# HR_C7000_DM32 register map
Vendor: Dahua Technology (chip); Baofeng (radio product); Series: HR_C7000; File version: 0.1-dm32re-draft
CPU: other r0p0, little endian, no MPU, no FPU, 0 interrupt priority bits
Registers are 32-bit, read-write, reset 0x0 unless marked. A register's access mark holds for its fields unless they carry their own. Offsets are from the block's base; [hi:lo] are bit positions; {n}, {i} and the like mark numbered series; <NAME> marks a mode.

## PIC (part 2 of 2) — Programmable interrupt controller, 64 sources of which Table 30 assigns 38 (DS §4.7, p.166-187; Register Table 5 p.170-172). This is the chip's real interrupt controller, not the CK803S built-in VIC at 0xE000E100: the stock firmware makes no 0xE000xxxx accesses (program-flash sweep and live register reads). SOURCE vs VECTOR: source n is bit n of PIC_MODE/PO/MASK/INT_ST/FFLAG_L (n < 32) or bit n-32 of PIC_MODE_1/PO_1/MASK_1/INT_ST_1/FFLAG_H, and byte n%4 of PIC_PRIOR<4*(n/4)>; the CPU sees it as vector n + PIC_VECTOR.vector0 = n + 32 at reset. Table 30 (p.168-169), source/vector: 0 reserved/32, 1 TIMER_1/33, 2 TIMER_2/34, 3 TIMER_3/35, 4 TIMER_4/36, 5 TIMER_5/37, 6 TIMER_6/38, 7 I2C1/39, 8 I2C0/40, 9 I2C2/41, 10 UART1/42, 11 UART2/43, 12 UART0/44, 13 UART3/45, 14 GPIOB/46, 15 GPIOA/47, 16 SPI0/48, 17 GPIOC/49, 18 PWM/50, 19 RTC/51, 20 SDIO/52, 21 USB/53, 22 SPI1/54, 23 SPI2/55, 24 LCSFC/56, 25 DAC/57, 26 ADC/58, 27 PCM_rd_data_interp/59, 28 PCM_wr_data_interp/60, 29 System_inter/61, 30 Time_slot_inter_tx/62, 31 Time_slot_inter_rx/63, 32 Rf_tx_inter/64, 33 Rf_rx_inter/65, 34 SlaveSPI0/66, 35 SlaveSPI1/67, 36 SlaveSPI2/68, 37 Codec_interp/69; all level-triggered, active high. CORRECTED 2026-10-10: the hand-maintained description this replaced listed CPU vectors as 'source assignments' (TIMER_1=33, TIMER_2-4=34-36, UART3=45, GPIOC=49, PCM_rd/wr_data_interp=59/60, System_inter=61, Time_slot_inter_rx=63, Rf_rx_inter=65, Codec_interp=69, and UART1/2/0=42/43/44, ADC=58, Rf_tx=64). Those are vectors; the sources are 1, 2-4, 13, 17, 27/28, 29, 31, 33, 37, 10/11/12, 26, 32. DRV's VECTOR_* defines (C7000_DRV.h: VECTOR_TIMER1-4=33-36, UART3=45, GPIOC=49, PCM_rd/wr_data_interp=59/60, System_inter=61, Time_slot_inter_rx=63, Rf_rx_inter=65, Codec_interp=69; bsp_vic.h: VECTOR_TIMER0=33, VECTOR_USB=53) are vectors too, passed to CKSetIsrVector, which unmasks bit (vector - 32); they agree with Table 30's vector column at every entry. The earlier note that a live trace's 'Time_slot_inter_tx = source 30' and DRV's 'Time_slot_inter_rx = 63' were an unverified TX/RX pair is resolved: Table 30 has tx at source 30/vector 62 and rx at source 31/vector 63. RTOS TICK: TIMER_1 (timer channel 0) is PIC source 1, CPU vector 33. Confirmed on hardware 2026-10-01 (OpenRTX bring-up on a DM-32UV, boot console log): with source 33 unmasked instead, the timer expired and held its line but nothing was delivered; with source 1 unmasked the ISR fired. The stock firmware registers its tick ISR with vector 33, stored at ISR-table index 33 - 32 = 1 (flash 0x0306cf70/0x0306cf38; dm32uv-qemu board-model notes (DM32-BOARD-MODEL.md), session 7). Register names and offsets also come from DRV bsp_vic.h ('Interrupt Controller definitions', Wang Huibin, 2013-05-13; in the DemoUV008 source tree at ucos3/include/bsp/bsp_vic.h), which agrees with Register Table 5 at every offset. Its CKIntcInit (bsp_vic.c) writes MODE = 0, PO = 0xffffffff, MASK = 0xffffffff, MODE_1 = 0, PO_1 = 0xffffffff, then MASK a second time where MASK_1 was probably meant, then INT_ST/INT_ST_1 = 0xffffffff. FW: 24 access sites in 2 code regions, all to MODE/PO/MASK/INT_ST and their upper-bank siblings; no access to PIC_VECTOR, PIC_COW1/2, PIC_PRIOR*, PIC_SYNC or PIC_FFLAG_* was found by the program-flash sweep, which does not cover IRAM (where the interrupt entry path runs).
Base 0x17000000
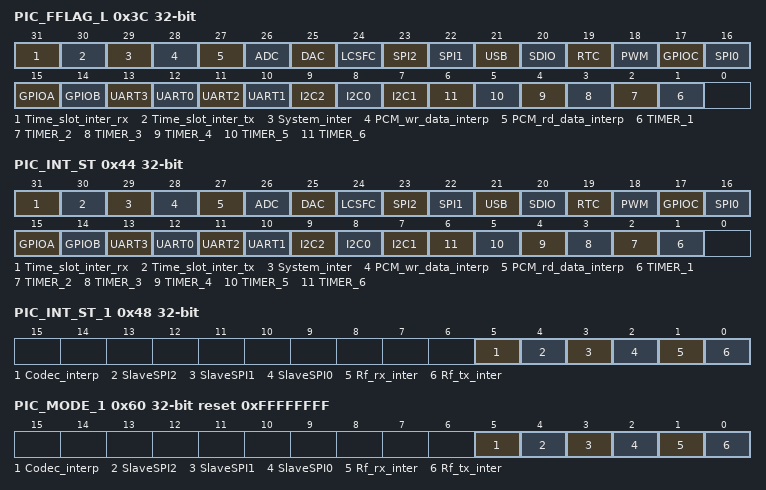
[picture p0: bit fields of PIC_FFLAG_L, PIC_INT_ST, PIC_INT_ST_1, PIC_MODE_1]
0x3C PIC_FFLAG_L — Fast-interrupt select, sources 0-31. DS §4.7.6.16 p.180. Bit n is source 0+n (sources 0-31). The datasheet prints one [31:0] field; it is split here into one bit per source named in Table 30 (p.168-169); bits with no assigned source have no field. The hand-maintained entry this replaced guessed a pending-interrupt flag word; it is the fast-interrupt select. Offset also in DRV bsp_vic.h. Reset 0x0 (DS).
  [31] Time_slot_inter_rx — source 31 (Time_slot_inter_rx, vector 63). 1: fast interrupt; 0: normal interrupt. The C7000 supports only normal interrupts (DS §4.7.4.1 p.170) [reset 0x0] [access RW]
  [30] Time_slot_inter_tx — source 30 (Time_slot_inter_tx, vector 62). 1: fast interrupt; 0: normal interrupt. The C7000 supports only normal interrupts (DS §4.7.4.1 p.170) [reset 0x0] [access RW]
  [29] System_inter — source 29 (System_inter, vector 61). 1: fast interrupt; 0: normal interrupt. The C7000 supports only normal interrupts (DS §4.7.4.1 p.170) [reset 0x0] [access RW]
  [28] PCM_wr_data_interp — source 28 (PCM_wr_data_interp, vector 60). 1: fast interrupt; 0: normal interrupt. The C7000 supports only normal interrupts (DS §4.7.4.1 p.170) [reset 0x0] [access RW]
  [27] PCM_rd_data_interp — source 27 (PCM_rd_data_interp, vector 59). 1: fast interrupt; 0: normal interrupt. The C7000 supports only normal interrupts (DS §4.7.4.1 p.170) [reset 0x0] [access RW]
  [26] ADC — source 26 (ADC, vector 58). 1: fast interrupt; 0: normal interrupt. The C7000 supports only normal interrupts (DS §4.7.4.1 p.170) [reset 0x0] [access RW]
  [25] DAC — source 25 (DAC, vector 57). 1: fast interrupt; 0: normal interrupt. The C7000 supports only normal interrupts (DS §4.7.4.1 p.170) [reset 0x0] [access RW]
  [24] LCSFC — source 24 (LCSFC, vector 56). 1: fast interrupt; 0: normal interrupt. The C7000 supports only normal interrupts (DS §4.7.4.1 p.170) [reset 0x0] [access RW]
  [23] SPI2 — source 23 (SPI2, vector 55). 1: fast interrupt; 0: normal interrupt. The C7000 supports only normal interrupts (DS §4.7.4.1 p.170) [reset 0x0] [access RW]
  [22] SPI1 — source 22 (SPI1, vector 54). 1: fast interrupt; 0: normal interrupt. The C7000 supports only normal interrupts (DS §4.7.4.1 p.170) [reset 0x0] [access RW]
  [21] USB — source 21 (USB, vector 53). 1: fast interrupt; 0: normal interrupt. The C7000 supports only normal interrupts (DS §4.7.4.1 p.170) [reset 0x0] [access RW]
  [20] SDIO — source 20 (SDIO, vector 52). 1: fast interrupt; 0: normal interrupt. The C7000 supports only normal interrupts (DS §4.7.4.1 p.170) [reset 0x0] [access RW]
  [19] RTC — source 19 (RTC, vector 51). 1: fast interrupt; 0: normal interrupt. The C7000 supports only normal interrupts (DS §4.7.4.1 p.170) [reset 0x0] [access RW]
  [18] PWM — source 18 (PWM, vector 50). 1: fast interrupt; 0: normal interrupt. The C7000 supports only normal interrupts (DS §4.7.4.1 p.170) [reset 0x0] [access RW]
  [17] GPIOC — source 17 (GPIOC, vector 49). 1: fast interrupt; 0: normal interrupt. The C7000 supports only normal interrupts (DS §4.7.4.1 p.170) [reset 0x0] [access RW]
  [16] SPI0 — source 16 (SPI0, vector 48). 1: fast interrupt; 0: normal interrupt. The C7000 supports only normal interrupts (DS §4.7.4.1 p.170) [reset 0x0] [access RW]
  [15] GPIOA — source 15 (GPIOA, vector 47). 1: fast interrupt; 0: normal interrupt. The C7000 supports only normal interrupts (DS §4.7.4.1 p.170) [reset 0x0] [access RW]
  [14] GPIOB — source 14 (GPIOB, vector 46). 1: fast interrupt; 0: normal interrupt. The C7000 supports only normal interrupts (DS §4.7.4.1 p.170) [reset 0x0] [access RW]
  [13] UART3 — source 13 (UART3, vector 45). 1: fast interrupt; 0: normal interrupt. The C7000 supports only normal interrupts (DS §4.7.4.1 p.170) [reset 0x0] [access RW]
  [12] UART0 — source 12 (UART0, vector 44). 1: fast interrupt; 0: normal interrupt. The C7000 supports only normal interrupts (DS §4.7.4.1 p.170) [reset 0x0] [access RW]
  [11] UART2 — source 11 (UART2, vector 43). 1: fast interrupt; 0: normal interrupt. The C7000 supports only normal interrupts (DS §4.7.4.1 p.170) [reset 0x0] [access RW]
  [10] UART1 — source 10 (UART1, vector 42). 1: fast interrupt; 0: normal interrupt. The C7000 supports only normal interrupts (DS §4.7.4.1 p.170) [reset 0x0] [access RW]
  [9] I2C2 — source 9 (I2C2, vector 41). 1: fast interrupt; 0: normal interrupt. The C7000 supports only normal interrupts (DS §4.7.4.1 p.170) [reset 0x0] [access RW]
  [8] I2C0 — source 8 (I2C0, vector 40). 1: fast interrupt; 0: normal interrupt. The C7000 supports only normal interrupts (DS §4.7.4.1 p.170) [reset 0x0] [access RW]
  [7] I2C1 — source 7 (I2C1, vector 39). 1: fast interrupt; 0: normal interrupt. The C7000 supports only normal interrupts (DS §4.7.4.1 p.170) [reset 0x0] [access RW]
  [n] TIMER_{n} (n=1..6) — source {n} (TIMER_{n}, vector {n+32}). 1: fast interrupt; 0: normal interrupt. The C7000 supports only normal interrupts (DS §4.7.4.1 p.170) [reset 0x0] [access RW]
0x40 PIC_RECORD_SEL — Selects the source whose requests PIC_INT_CNT counts. DS §4.7.6.17 p.180. Section heading prints PIC_INT_RECORD_SEL; Register Table 5 (p.172) and DRV bsp_vic.h call it PIC_RECORD_SEL, which is kept. Reset 0x0 (DS).
  [6:0] irq_record_sel — Source number whose requests (after synchronisation and masking) are counted in PIC_INT_CNT [reset 0x0] [access RW]
0x44 PIC_INT_ST — Interrupt request record, sources 0-31. DS §4.7.6.18 p.180. FW: 0 reads, 2 writes. Bit n is source 0+n (sources 0-31). The datasheet prints one [31:0] field; it is split here into one bit per source named in Table 30 (p.168-169); bits with no assigned source have no field. Write 0xffffffff to clear all records (DS §4.7.4.1 step 4). A 2026-10-09 firmware cross-reference found this word written all-ones at startup before the name was known, and DRV bsp_vic.h names it. Reset 0x0 (DS).
  [31] Time_slot_inter_rx write-1-clears — Request record for source 31 (Time_slot_inter_rx, vector 63): 1 = a request was seen (recorded once). Write 1 to clear the record and PIC_INT_CNT. Printed access RWC [reset 0x0] [access RWC]
  [30] Time_slot_inter_tx write-1-clears — Request record for source 30 (Time_slot_inter_tx, vector 62): 1 = a request was seen (recorded once). Write 1 to clear the record and PIC_INT_CNT. Printed access RWC [reset 0x0] [access RWC]
  [29] System_inter write-1-clears — Request record for source 29 (System_inter, vector 61): 1 = a request was seen (recorded once). Write 1 to clear the record and PIC_INT_CNT. Printed access RWC [reset 0x0] [access RWC]
  [28] PCM_wr_data_interp write-1-clears — Request record for source 28 (PCM_wr_data_interp, vector 60): 1 = a request was seen (recorded once). Write 1 to clear the record and PIC_INT_CNT. Printed access RWC [reset 0x0] [access RWC]
  [27] PCM_rd_data_interp write-1-clears — Request record for source 27 (PCM_rd_data_interp, vector 59): 1 = a request was seen (recorded once). Write 1 to clear the record and PIC_INT_CNT. Printed access RWC [reset 0x0] [access RWC]
  [26] ADC write-1-clears — Request record for source 26 (ADC, vector 58): 1 = a request was seen (recorded once). Write 1 to clear the record and PIC_INT_CNT. Printed access RWC [reset 0x0] [access RWC]
  [25] DAC write-1-clears — Request record for source 25 (DAC, vector 57): 1 = a request was seen (recorded once). Write 1 to clear the record and PIC_INT_CNT. Printed access RWC [reset 0x0] [access RWC]
  [24] LCSFC write-1-clears — Request record for source 24 (LCSFC, vector 56): 1 = a request was seen (recorded once). Write 1 to clear the record and PIC_INT_CNT. Printed access RWC [reset 0x0] [access RWC]
  [23] SPI2 write-1-clears — Request record for source 23 (SPI2, vector 55): 1 = a request was seen (recorded once). Write 1 to clear the record and PIC_INT_CNT. Printed access RWC [reset 0x0] [access RWC]
  [22] SPI1 write-1-clears — Request record for source 22 (SPI1, vector 54): 1 = a request was seen (recorded once). Write 1 to clear the record and PIC_INT_CNT. Printed access RWC [reset 0x0] [access RWC]
  [21] USB write-1-clears — Request record for source 21 (USB, vector 53): 1 = a request was seen (recorded once). Write 1 to clear the record and PIC_INT_CNT. Printed access RWC [reset 0x0] [access RWC]
  [20] SDIO write-1-clears — Request record for source 20 (SDIO, vector 52): 1 = a request was seen (recorded once). Write 1 to clear the record and PIC_INT_CNT. Printed access RWC [reset 0x0] [access RWC]
  [19] RTC write-1-clears — Request record for source 19 (RTC, vector 51): 1 = a request was seen (recorded once). Write 1 to clear the record and PIC_INT_CNT. Printed access RWC [reset 0x0] [access RWC]
  [18] PWM write-1-clears — Request record for source 18 (PWM, vector 50): 1 = a request was seen (recorded once). Write 1 to clear the record and PIC_INT_CNT. Printed access RWC [reset 0x0] [access RWC]
  [17] GPIOC write-1-clears — Request record for source 17 (GPIOC, vector 49): 1 = a request was seen (recorded once). Write 1 to clear the record and PIC_INT_CNT. Printed access RWC [reset 0x0] [access RWC]
  [16] SPI0 write-1-clears — Request record for source 16 (SPI0, vector 48): 1 = a request was seen (recorded once). Write 1 to clear the record and PIC_INT_CNT. Printed access RWC [reset 0x0] [access RWC]
  [15] GPIOA write-1-clears — Request record for source 15 (GPIOA, vector 47): 1 = a request was seen (recorded once). Write 1 to clear the record and PIC_INT_CNT. Printed access RWC [reset 0x0] [access RWC]
  [14] GPIOB write-1-clears — Request record for source 14 (GPIOB, vector 46): 1 = a request was seen (recorded once). Write 1 to clear the record and PIC_INT_CNT. Printed access RWC [reset 0x0] [access RWC]
  [13] UART3 write-1-clears — Request record for source 13 (UART3, vector 45): 1 = a request was seen (recorded once). Write 1 to clear the record and PIC_INT_CNT. Printed access RWC [reset 0x0] [access RWC]
  [12] UART0 write-1-clears — Request record for source 12 (UART0, vector 44): 1 = a request was seen (recorded once). Write 1 to clear the record and PIC_INT_CNT. Printed access RWC [reset 0x0] [access RWC]
  [11] UART2 write-1-clears — Request record for source 11 (UART2, vector 43): 1 = a request was seen (recorded once). Write 1 to clear the record and PIC_INT_CNT. Printed access RWC [reset 0x0] [access RWC]
  [10] UART1 write-1-clears — Request record for source 10 (UART1, vector 42): 1 = a request was seen (recorded once). Write 1 to clear the record and PIC_INT_CNT. Printed access RWC [reset 0x0] [access RWC]
  [9] I2C2 write-1-clears — Request record for source 9 (I2C2, vector 41): 1 = a request was seen (recorded once). Write 1 to clear the record and PIC_INT_CNT. Printed access RWC [reset 0x0] [access RWC]
  [8] I2C0 write-1-clears — Request record for source 8 (I2C0, vector 40): 1 = a request was seen (recorded once). Write 1 to clear the record and PIC_INT_CNT. Printed access RWC [reset 0x0] [access RWC]
  [7] I2C1 write-1-clears — Request record for source 7 (I2C1, vector 39): 1 = a request was seen (recorded once). Write 1 to clear the record and PIC_INT_CNT. Printed access RWC [reset 0x0] [access RWC]
  [n] TIMER_{n} write-1-clears (n=1..6) — Request record for source {n} (TIMER_{n}, vector {n+32}): 1 = a request was seen (recorded once). Write 1 to clear the record and PIC_INT_CNT. Printed access RWC [reset 0x0] [access RWC]
0x48 PIC_INT_ST_1 — Interrupt request record, sources 32-63. DS §4.7.6.19 p.181. FW: 0 reads, 2 writes. Bit n is source 32+n (sources 32-63). The datasheet prints one [31:0] field; it is split here into one bit per source named in Table 30 (p.168-169); bits with no assigned source have no field. Same history as PIC_INT_ST. Reset 0x0 (DS).
  [5] Codec_interp write-1-clears — Request record for source 37 (Codec_interp, vector 69): 1 = a request was seen (recorded once). Write 1 to clear the record and PIC_INT_CNT. Printed access RWC [reset 0x0] [access RWC]
  [4] SlaveSPI2 write-1-clears — Request record for source 36 (SlaveSPI2, vector 68): 1 = a request was seen (recorded once). Write 1 to clear the record and PIC_INT_CNT. Printed access RWC [reset 0x0] [access RWC]
  [3] SlaveSPI1 write-1-clears — Request record for source 35 (SlaveSPI1, vector 67): 1 = a request was seen (recorded once). Write 1 to clear the record and PIC_INT_CNT. Printed access RWC [reset 0x0] [access RWC]
  [2] SlaveSPI0 write-1-clears — Request record for source 34 (SlaveSPI0, vector 66): 1 = a request was seen (recorded once). Write 1 to clear the record and PIC_INT_CNT. Printed access RWC [reset 0x0] [access RWC]
  [1] Rf_rx_inter write-1-clears — Request record for source 33 (Rf_rx_inter, vector 65): 1 = a request was seen (recorded once). Write 1 to clear the record and PIC_INT_CNT. Printed access RWC [reset 0x0] [access RWC]
  [0] Rf_tx_inter write-1-clears — Request record for source 32 (Rf_tx_inter, vector 64): 1 = a request was seen (recorded once). Write 1 to clear the record and PIC_INT_CNT. Printed access RWC [reset 0x0] [access RWC]
0x4C PIC_INT_CNT ro — Interrupt source interrupt count. DS §4.7.6.20 p.181. Section heading prints PIC_INT_ST_CNT at offset 0x48, which collides with PIC_INT_ST_1 (both editions); Register Table 5 (p.172) and DRV bsp_vic.h give PIC_INT_CNT at 0x4c, which is used. The hand-maintained entry this replaced guessed a spurious/total counter; it counts only the source selected by PIC_RECORD_SEL. Reset 0x0 (DS).
  [31:0] int_cnt — Number of interrupt requests from the source selected by PIC_RECORD_SEL (printed PIC_INT_RECORD_SEL) [reset 0x0] [access RO]
0x60 PIC_MODE_1 reset 0xFFFFFFFF — Trigger mode select, sources 32-63 (Register Table 5 prints 'Height 32', i.e. the high 32). DS §4.7.6.21 p.182. FW: 0 reads, 2 writes. Bit n is source 32+n (sources 32-63). The datasheet prints one [31:0] field; it is split here into one bit per source named in Table 30 (p.168-169); bits with no assigned source have no field. A 2026-10-09 firmware cross-reference found this offset written all-ones at startup and labelled it RESERVED_0x60 before DRV bsp_vic.h gave the name. Reset 0xffffffff (DS).
  [5] Codec_interp — Trigger mode of source 37 (Codec_interp, vector 69). 1: edge; 0: level. Table 30 specifies level-triggered, active high [reset 0x1] [access RW]
  [4] SlaveSPI2 — Trigger mode of source 36 (SlaveSPI2, vector 68). 1: edge; 0: level. Table 30 specifies level-triggered, active high [reset 0x1] [access RW]
  [3] SlaveSPI1 — Trigger mode of source 35 (SlaveSPI1, vector 67). 1: edge; 0: level. Table 30 specifies level-triggered, active high [reset 0x1] [access RW]
  [2] SlaveSPI0 — Trigger mode of source 34 (SlaveSPI0, vector 66). 1: edge; 0: level. Table 30 specifies level-triggered, active high [reset 0x1] [access RW]
  [1] Rf_rx_inter — Trigger mode of source 33 (Rf_rx_inter, vector 65). 1: edge; 0: level. Table 30 specifies level-triggered, active high [reset 0x1] [access RW]
  [0] Rf_tx_inter — Trigger mode of source 32 (Rf_tx_inter, vector 64). 1: edge; 0: level. Table 30 specifies level-triggered, active high [reset 0x1] [access RW]
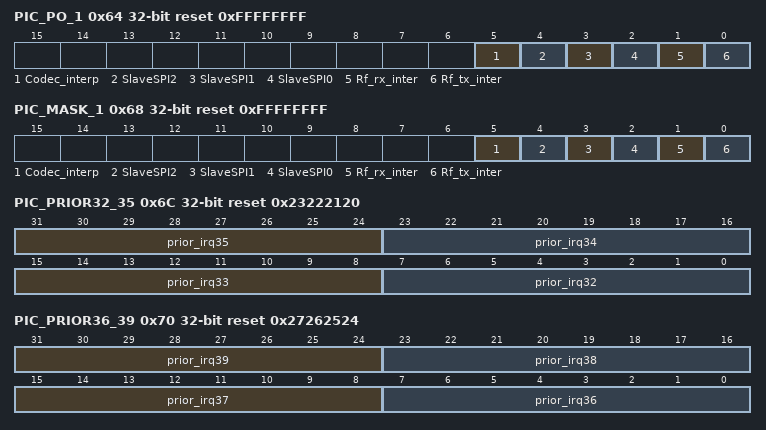
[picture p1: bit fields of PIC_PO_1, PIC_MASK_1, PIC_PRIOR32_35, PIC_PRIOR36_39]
0x64 PIC_PO_1 reset 0xFFFFFFFF — Trigger polarity select, sources 32-63 (Register Table 5 prints 'Height 32', i.e. the high 32). DS §4.7.6.22 p.182. FW: 0 reads, 2 writes. Bit n is source 32+n (sources 32-63). The datasheet prints one [31:0] field; it is split here into one bit per source named in Table 30 (p.168-169); bits with no assigned source have no field. Offset also in DRV bsp_vic.h. Reset 0xffffffff (DS).
  [5] Codec_interp — Trigger polarity of source 37 (Codec_interp, vector 69). 1: rising edge / high level; 0: falling edge / low level [reset 0x1] [access RW]
  [4] SlaveSPI2 — Trigger polarity of source 36 (SlaveSPI2, vector 68). 1: rising edge / high level; 0: falling edge / low level [reset 0x1] [access RW]
  [3] SlaveSPI1 — Trigger polarity of source 35 (SlaveSPI1, vector 67). 1: rising edge / high level; 0: falling edge / low level [reset 0x1] [access RW]
  [2] SlaveSPI0 — Trigger polarity of source 34 (SlaveSPI0, vector 66). 1: rising edge / high level; 0: falling edge / low level [reset 0x1] [access RW]
  [1] Rf_rx_inter — Trigger polarity of source 33 (Rf_rx_inter, vector 65). 1: rising edge / high level; 0: falling edge / low level [reset 0x1] [access RW]
  [0] Rf_tx_inter — Trigger polarity of source 32 (Rf_tx_inter, vector 64). 1: rising edge / high level; 0: falling edge / low level [reset 0x1] [access RW]
0x68 PIC_MASK_1 reset 0xFFFFFFFF — Interrupt mask, sources 32-63 (Register Table 5 prints 'Height 32', i.e. the high 32). DS §4.7.6.23 p.182. FW: 2 reads, 4 writes. Bit n is source 32+n (sources 32-63). The datasheet prints one [31:0] field; it is split here into one bit per source named in Table 30 (p.168-169); bits with no assigned source have no field. FW clears bit (v - 0x40) here for CPU vector v >= 0x40 (same two functions as PIC_MASK). Hardware, 2026-10-01 (OpenRTX bring-up on a DM-32UV, boot console log): an OpenRTX build that cleared bit 1 here (source 33) read PIC_MASK/PIC_MASK_1 = ffffffff/fffffffd, the timer counted and held its line, and no interrupt was delivered; clearing bit 1 of PIC_MASK (source 1, TIMER_1) made the tick ISR fire. Named PIC_MASK_HI in earlier drafts until DRV bsp_vic.h gave PIC_MASK_1 (2026-10-09). CORRECTED 2026-10-10: the entry this replaced said this word covers sources 64+; it covers 32-63. Reset 0xffffffff (DS).
  [5] Codec_interp — Mask for source 37 (Codec_interp, vector 69). 1: masked; 0: request detection enabled [reset 0x1] [access RW]
  [4] SlaveSPI2 — Mask for source 36 (SlaveSPI2, vector 68). 1: masked; 0: request detection enabled [reset 0x1] [access RW]
  [3] SlaveSPI1 — Mask for source 35 (SlaveSPI1, vector 67). 1: masked; 0: request detection enabled [reset 0x1] [access RW]
  [2] SlaveSPI0 — Mask for source 34 (SlaveSPI0, vector 66). 1: masked; 0: request detection enabled [reset 0x1] [access RW]
  [1] Rf_rx_inter — Mask for source 33 (Rf_rx_inter, vector 65). 1: masked; 0: request detection enabled [reset 0x1] [access RW]
  [0] Rf_tx_inter — Mask for source 32 (Rf_tx_inter, vector 64). 1: masked; 0: request detection enabled [reset 0x1] [access RW]
0x6C PIC_PRIOR32_35 reset 0x23222120 — Priority counter initial values, sources 32-35. DS §4.7.6.24 p.182. Sources 32-35 are Rf_tx_inter, Rf_rx_inter, SlaveSPI0, SlaveSPI1; one byte each, source 32 in [7:0]. Offset also in DRV bsp_vic.h as PIC_PRIOR32_35. FW: no access found by the program-flash sweep (which does not cover IRAM code). Both v2.7 editions print the defaults as 0x27/0x26/0x25/0x24 (for sources 35..32), the same values as PIC_PRIOR36-39, and print the rows in Chinese. Every other PRIOR register's default equals its source number, so 0x23/0x22/0x21/0x20 are used (INFERRED; reset 0x23222120 here, printed values would give 0x27262524). Reset 0x23222120 (DS).
  [31:24] prior_irq35 — Priority counter initial value for source 35 (SlaveSPI1, vector 67); smaller is higher priority. Used only when PIC_COW2.priority = 1. Reset value n gives the same order as the fixed default IRQ0 > IRQ1 > ... > IRQ63 [reset 0x23] [access RW]
  [23:16] prior_irq34 — Priority counter initial value for source 34 (SlaveSPI0, vector 66); smaller is higher priority. Used only when PIC_COW2.priority = 1. Reset value n gives the same order as the fixed default IRQ0 > IRQ1 > ... > IRQ63 [reset 0x22] [access RW]
  [15:8] prior_irq33 — Priority counter initial value for source 33 (Rf_rx_inter, vector 65); smaller is higher priority. Used only when PIC_COW2.priority = 1. Reset value n gives the same order as the fixed default IRQ0 > IRQ1 > ... > IRQ63 [reset 0x21] [access RW]
  [7:0] prior_irq32 — Priority counter initial value for source 32 (Rf_tx_inter, vector 64); smaller is higher priority. Used only when PIC_COW2.priority = 1. Reset value n gives the same order as the fixed default IRQ0 > IRQ1 > ... > IRQ63 [reset 0x20] [access RW]
0x70 PIC_PRIOR36_39 reset 0x27262524 — Priority counter initial values, sources 36-39. DS §4.7.6.25 p.184. Sources 36-39 are SlaveSPI2, Codec_interp, unassigned, unassigned; one byte each, source 36 in [7:0]. Offset also in DRV bsp_vic.h as PIC_PRIOR36_39. FW: no access found by the program-flash sweep (which does not cover IRAM code). Reset 0x27262524 (DS).
  [31:24] prior_irq39 — Priority counter initial value for source 39 (not assigned in Table 30); smaller is higher priority. Used only when PIC_COW2.priority = 1. Reset value n gives the same order as the fixed default IRQ0 > IRQ1 > ... > IRQ63 [reset 0x27] [access RW]
  [23:16] prior_irq38 — Priority counter initial value for source 38 (not assigned in Table 30); smaller is higher priority. Used only when PIC_COW2.priority = 1. Reset value n gives the same order as the fixed default IRQ0 > IRQ1 > ... > IRQ63 [reset 0x26] [access RW]
  [15:8] prior_irq37 — Priority counter initial value for source 37 (Codec_interp, vector 69); smaller is higher priority. Used only when PIC_COW2.priority = 1. Reset value n gives the same order as the fixed default IRQ0 > IRQ1 > ... > IRQ63 [reset 0x25] [access RW]
  [7:0] prior_irq36 — Priority counter initial value for source 36 (SlaveSPI2, vector 68); smaller is higher priority. Used only when PIC_COW2.priority = 1. Reset value n gives the same order as the fixed default IRQ0 > IRQ1 > ... > IRQ63 [reset 0x24] [access RW]
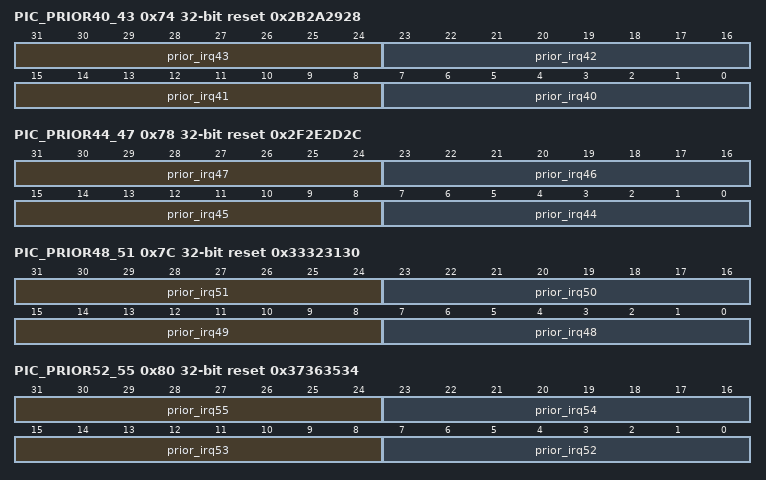
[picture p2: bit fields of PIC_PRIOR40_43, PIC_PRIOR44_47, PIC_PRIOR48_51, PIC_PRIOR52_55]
0x74 PIC_PRIOR40_43 reset 0x2B2A2928 — Priority counter initial values, sources 40-43. DS §4.7.6.26 p.184. Sources 40-43 are unassigned, unassigned, unassigned, unassigned; one byte each, source 40 in [7:0]. Offset also in DRV bsp_vic.h as PIC_PRIOR40_43. FW: no access found by the program-flash sweep (which does not cover IRAM code). Reset 0x2b2a2928 (DS).
  [31:24] prior_irq43 — Priority counter initial value for source 43 (not assigned in Table 30); smaller is higher priority. Used only when PIC_COW2.priority = 1. Reset value n gives the same order as the fixed default IRQ0 > IRQ1 > ... > IRQ63 [reset 0x2b] [access RW]
  [23:16] prior_irq42 — Priority counter initial value for source 42 (not assigned in Table 30); smaller is higher priority. Used only when PIC_COW2.priority = 1. Reset value n gives the same order as the fixed default IRQ0 > IRQ1 > ... > IRQ63 [reset 0x2a] [access RW]
  [15:8] prior_irq41 — Priority counter initial value for source 41 (not assigned in Table 30); smaller is higher priority. Used only when PIC_COW2.priority = 1. Reset value n gives the same order as the fixed default IRQ0 > IRQ1 > ... > IRQ63 [reset 0x29] [access RW]
  [7:0] prior_irq40 — Priority counter initial value for source 40 (not assigned in Table 30); smaller is higher priority. Used only when PIC_COW2.priority = 1. Reset value n gives the same order as the fixed default IRQ0 > IRQ1 > ... > IRQ63 [reset 0x28] [access RW]
0x78 PIC_PRIOR44_47 reset 0x2F2E2D2C — Priority counter initial values, sources 44-47. DS §4.7.6.27 p.184. Sources 44-47 are unassigned, unassigned, unassigned, unassigned; one byte each, source 44 in [7:0]. Offset also in DRV bsp_vic.h as PIC_PRIOR44_47. FW: no access found by the program-flash sweep (which does not cover IRAM code). Reset 0x2f2e2d2c (DS).
  [31:24] prior_irq47 — Priority counter initial value for source 47 (not assigned in Table 30); smaller is higher priority. Used only when PIC_COW2.priority = 1. Reset value n gives the same order as the fixed default IRQ0 > IRQ1 > ... > IRQ63 [reset 0x2f] [access RW]
  [23:16] prior_irq46 — Priority counter initial value for source 46 (not assigned in Table 30); smaller is higher priority. Used only when PIC_COW2.priority = 1. Reset value n gives the same order as the fixed default IRQ0 > IRQ1 > ... > IRQ63 [reset 0x2e] [access RW]
  [15:8] prior_irq45 — Priority counter initial value for source 45 (not assigned in Table 30); smaller is higher priority. Used only when PIC_COW2.priority = 1. Reset value n gives the same order as the fixed default IRQ0 > IRQ1 > ... > IRQ63 [reset 0x2d] [access RW]
  [7:0] prior_irq44 — Priority counter initial value for source 44 (not assigned in Table 30); smaller is higher priority. Used only when PIC_COW2.priority = 1. Reset value n gives the same order as the fixed default IRQ0 > IRQ1 > ... > IRQ63 [reset 0x2c] [access RW]
0x7C PIC_PRIOR48_51 reset 0x33323130 — Priority counter initial values, sources 48-51. DS §4.7.6.28 p.185. Sources 48-51 are unassigned, unassigned, unassigned, unassigned; one byte each, source 48 in [7:0]. Offset also in DRV bsp_vic.h as PIC_PRIOR48_51. FW: no access found by the program-flash sweep (which does not cover IRAM code). Reset 0x33323130 (DS).
  [31:24] prior_irq51 — Priority counter initial value for source 51 (not assigned in Table 30); smaller is higher priority. Used only when PIC_COW2.priority = 1. Reset value n gives the same order as the fixed default IRQ0 > IRQ1 > ... > IRQ63 [reset 0x33] [access RW]
  [23:16] prior_irq50 — Priority counter initial value for source 50 (not assigned in Table 30); smaller is higher priority. Used only when PIC_COW2.priority = 1. Reset value n gives the same order as the fixed default IRQ0 > IRQ1 > ... > IRQ63 [reset 0x32] [access RW]
  [15:8] prior_irq49 — Priority counter initial value for source 49 (not assigned in Table 30); smaller is higher priority. Used only when PIC_COW2.priority = 1. Reset value n gives the same order as the fixed default IRQ0 > IRQ1 > ... > IRQ63 [reset 0x31] [access RW]
  [7:0] prior_irq48 — Priority counter initial value for source 48 (not assigned in Table 30); smaller is higher priority. Used only when PIC_COW2.priority = 1. Reset value n gives the same order as the fixed default IRQ0 > IRQ1 > ... > IRQ63 [reset 0x30] [access RW]
0x80 PIC_PRIOR52_55 reset 0x37363534 — Priority counter initial values, sources 52-55. DS §4.7.6.29 p.185. Sources 52-55 are unassigned, unassigned, unassigned, unassigned; one byte each, source 52 in [7:0]. Offset also in DRV bsp_vic.h as PIC_PRIOR52_55. FW: no access found by the program-flash sweep (which does not cover IRAM code). Reset 0x37363534 (DS).
  [31:24] prior_irq55 — Priority counter initial value for source 55 (not assigned in Table 30); smaller is higher priority. Used only when PIC_COW2.priority = 1. Reset value n gives the same order as the fixed default IRQ0 > IRQ1 > ... > IRQ63 [reset 0x37] [access RW]
  [23:16] prior_irq54 — Priority counter initial value for source 54 (not assigned in Table 30); smaller is higher priority. Used only when PIC_COW2.priority = 1. Reset value n gives the same order as the fixed default IRQ0 > IRQ1 > ... > IRQ63 [reset 0x36] [access RW]
  [15:8] prior_irq53 — Priority counter initial value for source 53 (not assigned in Table 30); smaller is higher priority. Used only when PIC_COW2.priority = 1. Reset value n gives the same order as the fixed default IRQ0 > IRQ1 > ... > IRQ63 [reset 0x35] [access RW]
  [7:0] prior_irq52 — Priority counter initial value for source 52 (not assigned in Table 30); smaller is higher priority. Used only when PIC_COW2.priority = 1. Reset value n gives the same order as the fixed default IRQ0 > IRQ1 > ... > IRQ63 [reset 0x34] [access RW]
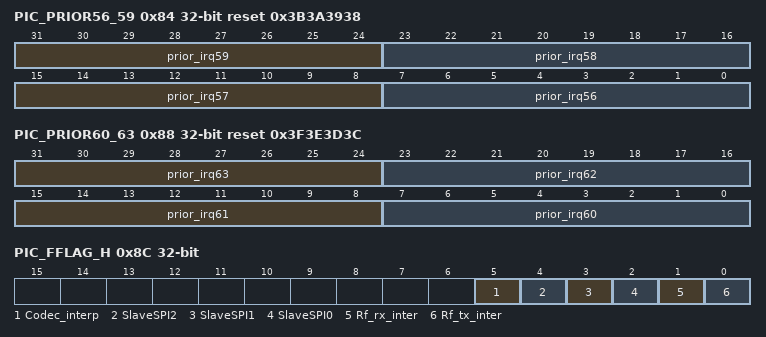
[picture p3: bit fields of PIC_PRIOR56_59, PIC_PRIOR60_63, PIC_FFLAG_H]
0x84 PIC_PRIOR56_59 reset 0x3B3A3938 — Priority counter initial values, sources 56-59. DS §4.7.6.30 p.186. Sources 56-59 are unassigned, unassigned, unassigned, unassigned; one byte each, source 56 in [7:0]. Offset also in DRV bsp_vic.h as PIC_PRIOR56_59. FW: no access found by the program-flash sweep (which does not cover IRAM code). Reset 0x3b3a3938 (DS).
  [31:24] prior_irq59 — Priority counter initial value for source 59 (not assigned in Table 30); smaller is higher priority. Used only when PIC_COW2.priority = 1. Reset value n gives the same order as the fixed default IRQ0 > IRQ1 > ... > IRQ63 [reset 0x3b] [access RW]
  [23:16] prior_irq58 — Priority counter initial value for source 58 (not assigned in Table 30); smaller is higher priority. Used only when PIC_COW2.priority = 1. Reset value n gives the same order as the fixed default IRQ0 > IRQ1 > ... > IRQ63 [reset 0x3a] [access RW]
  [15:8] prior_irq57 — Priority counter initial value for source 57 (not assigned in Table 30); smaller is higher priority. Used only when PIC_COW2.priority = 1. Reset value n gives the same order as the fixed default IRQ0 > IRQ1 > ... > IRQ63 [reset 0x39] [access RW]
  [7:0] prior_irq56 — Priority counter initial value for source 56 (not assigned in Table 30); smaller is higher priority. Used only when PIC_COW2.priority = 1. Reset value n gives the same order as the fixed default IRQ0 > IRQ1 > ... > IRQ63 [reset 0x38] [access RW]
0x88 PIC_PRIOR60_63 reset 0x3F3E3D3C — Priority counter initial values, sources 60-63. DS §4.7.6.31 p.186. Sources 60-63 are unassigned, unassigned, unassigned, unassigned; one byte each, source 60 in [7:0]. Offset also in DRV bsp_vic.h as PIC_PRIOR60_63. FW: no access found by the program-flash sweep (which does not cover IRAM code). Reset 0x3f3e3d3c (DS).
  [31:24] prior_irq63 — Priority counter initial value for source 63 (not assigned in Table 30); smaller is higher priority. Used only when PIC_COW2.priority = 1. Reset value n gives the same order as the fixed default IRQ0 > IRQ1 > ... > IRQ63 [reset 0x3f] [access RW]
  [23:16] prior_irq62 — Priority counter initial value for source 62 (not assigned in Table 30); smaller is higher priority. Used only when PIC_COW2.priority = 1. Reset value n gives the same order as the fixed default IRQ0 > IRQ1 > ... > IRQ63 [reset 0x3e] [access RW]
  [15:8] prior_irq61 — Priority counter initial value for source 61 (not assigned in Table 30); smaller is higher priority. Used only when PIC_COW2.priority = 1. Reset value n gives the same order as the fixed default IRQ0 > IRQ1 > ... > IRQ63 [reset 0x3d] [access RW]
  [7:0] prior_irq60 — Priority counter initial value for source 60 (not assigned in Table 30); smaller is higher priority. Used only when PIC_COW2.priority = 1. Reset value n gives the same order as the fixed default IRQ0 > IRQ1 > ... > IRQ63 [reset 0x3c] [access RW]
0x8C PIC_FFLAG_H — Fast-interrupt select, sources 32-63 (Register Table 5 prints 'Height 32', i.e. the high 32). DS §4.7.6.32 p.186. Bit n is source 32+n (sources 32-63). The datasheet prints one [31:0] field; it is split here into one bit per source named in Table 30 (p.168-169); bits with no assigned source have no field. Offset also in DRV bsp_vic.h. Reset 0x0 (DS).
  [5] Codec_interp — source 37 (Codec_interp, vector 69). 1: fast interrupt; 0: normal interrupt. The C7000 supports only normal interrupts (DS §4.7.4.1 p.170) [reset 0x0] [access RW]
  [4] SlaveSPI2 — source 36 (SlaveSPI2, vector 68). 1: fast interrupt; 0: normal interrupt. The C7000 supports only normal interrupts (DS §4.7.4.1 p.170) [reset 0x0] [access RW]
  [3] SlaveSPI1 — source 35 (SlaveSPI1, vector 67). 1: fast interrupt; 0: normal interrupt. The C7000 supports only normal interrupts (DS §4.7.4.1 p.170) [reset 0x0] [access RW]
  [2] SlaveSPI0 — source 34 (SlaveSPI0, vector 66). 1: fast interrupt; 0: normal interrupt. The C7000 supports only normal interrupts (DS §4.7.4.1 p.170) [reset 0x0] [access RW]
  [1] Rf_rx_inter — source 33 (Rf_rx_inter, vector 65). 1: fast interrupt; 0: normal interrupt. The C7000 supports only normal interrupts (DS §4.7.4.1 p.170) [reset 0x0] [access RW]
  [0] Rf_tx_inter — source 32 (Rf_tx_inter, vector 64). 1: fast interrupt; 0: normal interrupt. The C7000 supports only normal interrupts (DS §4.7.4.1 p.170) [reset 0x0] [access RW]
